# SCR_TC3xx register map
Vendor: Infineon; File version: 1.0
Registers are 8-bit, read-write, reset 0x0 unless marked. A register's access mark holds for its fields unless they carry their own. Offsets are from the block's base; [hi:lo] are bit positions; {n}, {i} and the like mark numbered series.

## SCR_WCAN — SCR Wake-up CAN filter
Base 0x00040000
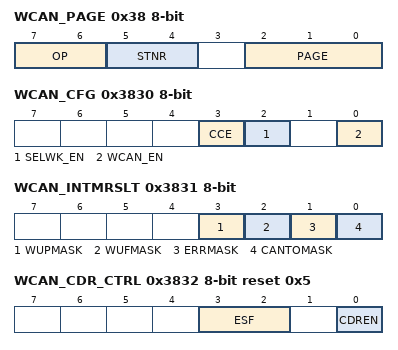
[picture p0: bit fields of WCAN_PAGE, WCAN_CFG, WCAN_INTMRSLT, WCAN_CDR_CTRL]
0x38 WCAN_PAGE — Page Register for WCAN (SFR 0xB8, RMAP 0)
  [7:6] OP — Operation. [w]
    0=PAGE_MANUAL0 (Manual page mode. The value of STNR is ignored and PAGE is directly written.); 1=PAGE_MANUAL1 (Manual page mode. The value of STNR is ignored and PAGE is directly written); 2=PAGE_SAVE (New page programming with automatic page saving. The value written to the bit positions of PAGE is stored. In parallel, the former contents of PAGE are saved in the storage bit field STx indicated by STNR.); 3=PAGE_RESTORE (Automatic restore page action. The value written to the bit positions PAGE is ignored and instead, PAGE is overwritten by the contents of the storage bit field STx indicated by STNR.)
  [5:4] STNR — Storage Number. This number indicates which storage bitfield is the target of the operation defined by bit OP. If OP = 10B, the contents of PAGE are saved in STx before being overwritten with the new value. If OP = 11B, the contents of PAGE are overwritten by the contents of STx. The value written to bitfield PAGE is ignored. [w]
    {v}=MOD_ST{v} (ST{v} is selected) (v=0..3)
  [2:0] PAGE — Page Bits. When written, the value indicates the new page address. When read, the value indicates the currently active page = addr[y:x+1]. [rw]
    {v}=Selection is PAGE{v} (v=0..7)
0x3830 WCAN_CFG — Wake-Up CAN Configuration Register (SFR 0xB0, WCAN_PAGE page 0, RMAP 0)
  [3] CCE — Configuration Change Enable. This bit field enables the configuration of the Bit Timing Registers. It also acts as soft-reset to the Selective Wake-up filter block. It has to be set back to '0' once the bit timing registers are modified for desired baudrate. [rw]
    0=THE_BIT_TIMING_REGISTERS_BTLN (The Bit Timing Registers (BTLn_CTRL), CDR Configuration registers (CDR_CTRL, CDR_UPPER_CTRL, CDR_LOWER_CTRL) and CAN_FD_CTRL may only be read. All attempts to modify them will be ignored.); 1=THE_BIT_TIMING_REGISTERS_AND_CDR (The Bit Timing Registers and CDR Configuration registers may be read and written)
  [2] SELWK_EN — Selective Wake-Up Enable. The Selective Wake-up Enable function enables the protocol handler. The status of the protocol handler is also acknowledged through INTESTAT0.SWACK. The status of the Selective Wakeup Active is given in INTESTAT1.SWKSET. It also serves several functions when enabled. 1.Allows Wake-up source WUF to generate WUF_INT (see Figure "Wake- up Frame Detection"). 2.Allows error counter to generate ERROR_INT (see Figure "Error Counter"), indicated by INTESTAT0.ECOFL. 3.Triggers ERROR_INT and wake-up if there are any changes to the message object registers, indicated by INTESTAT0.MORC. 4.If a SYSERR occurs while SELWK_EN is enabled, then the Selective Wake-up function shall be disabled (ie., this bit field will be reset to 0). It is also indicated by INTESTAT0.ERSEL. [rwh]
    0=SELECTIVE_WAKE_DISABLED; 1=SELECTIVE_WAKE_ENABLED
  [0] WCAN_EN — WCAN Enable. This bit enables or disables the clock to WCAN Selective Wake-Up filter block. [rw]
    0=DISABLE_CLOCK_TO_WCAN_SELECTIVE (Disable Clock to WCAN Selective Wake-Up filter block); 1=ENABLE_CLOCK_TO_WCAN_SELECTIVE (Enable Clock to WCAN Selective Wake-Up filter block)
0x3831 WCAN_INTMRSLT — Wake-Up CAN Interrupt Mask Register (SFR 0xB1, WCAN_PAGE page 0, RMAP 0)
  [3] WUPMASK — Wake-Up Pattern Detected Interrupt Masking. This bit controls the interrupt masking for WUP_INT interrupt. [rw]
    0=WUP_INT_IS_MASKED_NO_INTERRUPT_IS (WUP_INT is masked - no interrupt is triggered); 1=WUP_INT_IS_SIGNALED_AS_AN (WUP_INT is signaled as an interrupt)
  [2] WUFMASK — Wake-Up Frame Interrupt Masking. This bit controls the interrupt masking for WUF_INT interrupt. [rw]
    0=WUF_INT_IS_MASKED_NO_INTERRUPT_IS (WUF_INT is masked - no interrupt is triggered); 1=WUF_INT_IS_SIGNALED_AS_AN (WUF_INT is signaled as an interrupt)
  [1] ERRMASK — SYSERR Masking. This bit controls the interrupt masking for SYSERR interrupt. [rw]
    0=SYSERR_IS_MASKED_NO_INTERRUPT_IS (SYSERR is masked - no interrupt is triggered); 1=SYSERR_IS_SIGNALED_AS_AN (SYSERR is signaled as an interrupt)
  [0] CANTOMASK — CAN Time-Out Masking. This bit controls the interrupt masking for CANTO_INT interrupt. [rw]
    0=CAN_TIME_OUT_IS_MASKED_NO (CAN Time-Out is masked - no interrupt is triggered); 1=CAN_TIME_OUT_IS_SIGNALED_AS_AN (CAN Time-Out is signaled as an interrupt)
0x3832 WCAN_CDR_CTRL reset 0x5 — CDR Control Register (SFR 0xB2, WCAN_PAGE page 0, RMAP 0)
  [3:2] ESF — Error scaling factor. This bitfield defines the number of acquisition cycles on which average on error is calculated. [rw]
    0=ERR_SCALE_FACT8 (8); 1=ERR_SCALE_FACT16 (16 (recommended)); 2=ERR_SCALE_FACT32 (32); 3=ADAPT_AVRGE (Adaptive averaging)
  [0] CDREN — Enable CDR. [rw]
    0=DISABLE_CDR_INTERNAL_BIT_TIME (Disable CDR internal bit time measurement); 1=ENABLE_CDR_INTERNAL_BIT_TIME (Enable CDR internal bit time measurement)
0x3833 WCAN_CDR_UPPER_CTRL reset 0x69 — CDR Upper Limit Control Register (SFR 0xB3, WCAN_PAGE page 0, RMAP 0)
  [7:0] UPPER — CDR Upper Limit. This bitfield defines the upper limit for CDR internal bit time measurement. It should be configured as +5% of BTL1_CTRL value (integer part). [rw]
0x3834 WCAN_CDR_LOWER_CTRL reset 0x5F — CDR Lower Limit Control Register (SFR 0xB4, WCAN_PAGE page 0, RMAP 0)
  [7:0] LOWER — CDR Lower Limit. This bitfield defines the lower limit for CDR internal bit time measurement. It should be configured as -5% of BTL1_CTRL value (integer part). [rw]
0x3835 WCAN_CDR_MEAS_HIGH ro reset 0x64 — CDR Measured High Register (SFR 0xB5, WCAN_PAGE page 0, RMAP 0)
  [7:0] HIGH — CDR Internally Measured High Value. This bitfield shows the internally measured duration of a CAN bus bit as number of fCAN clock cycles (integer part). [rh]
0x3836 WCAN_CDR_MEAS_LOW ro — CDR Measured Low Register (SFR 0xB6, WCAN_PAGE page 0, RMAP 0)
  [5:0] LOW — CDR Internally Measured Low Value. This bitfield shows the internally measured duration of a CAN bus bit as number of fCAN clock cycles (fractional part). [rh]
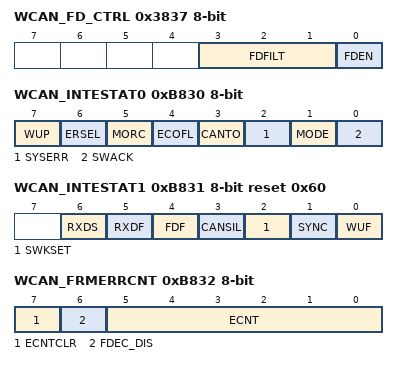
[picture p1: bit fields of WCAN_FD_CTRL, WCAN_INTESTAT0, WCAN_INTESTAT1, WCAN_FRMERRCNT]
0x3837 WCAN_FD_CTRL — CAN FD Control Register (SFR 0xB7, WCAN_PAGE page 0, RMAP 0)
  [3:1] FDFILT — CAN FD Filter Time. This bitfield configures the filter time to detect the dominant bit field in FD phase. Refer to Table "CAN FD dominant bit filter time" for the FD filter time configuration for various baudrates. others, Reserved [rw]
    0=V13_130_NS (13 (130 ns)); 1=V25_250_NS (25 (250 ns)); 2=V48_480_NS (48 (480 ns)); 3=V90_900_NS (90 (900 ns))
  [0] FDEN — CAN FD Tolerant Enable. This bitfield enables or disables the CAN FD tolerant feature. [rw]
    0=DISABLED; 1=ENABLED
0xB830 WCAN_INTESTAT0 ro — Wake-Up CAN Interrupt and Event Status Register 0 (SFR 0xB0, WCAN_PAGE page 1, RMAP 0)
  [7] WUP — Wake-Up Pattern Detected. This bit field is set when a falling edge on RXD (or WUP) is detected, when WCAN is in Standby mode. A software write to INTESTATCLR0.WUPCLR is required to clear this bit field. [rh]
    0=WUP_NOT_DETECTED; 1=WUP_DETECTED_IT_ALSO_TRIGGERS_WUP (WUP detected. It also triggers WUP_INT interrupt when enabled through INTMRSLT.WUPMASK)
  [6] ERSEL — Error Select. A set condition of this flag by hardware has higher priority than a clear through ERSELCLR. [rh]
    0=SYSERR_IS_NOT_SET_WHILE_SELWK_EN (SYSERR is not set while SELWK_EN is enabled); 1=SYSERR_IS_SET_WHILE_SELWK_EN_IS (SYSERR is set while SELWK_EN is enabled)
  [5] MORC — Message Object Register Changed. A set condition of this flag by hardware has higher priority than a clear through MORCCLR. [rh]
    0=MESSAGE_OBJECT_REGISTERS_NOT (Message object registers not modified after SELWK_EN is set); 1=MESSAGE_OBJECT_REGISTERS_WAS (Message object registers was modified after SELWK_EN is set)
  [4] ECOFL — Error Counter Overflow. This bit field shows occurrence of Error Counter overflow. A set condition of this flag by hardware has higher priority than a clear through ECOFLCLR. [rh]
    0=ERROR_COUNTER_HAS_NOT_OVERFLOWED (Error Counter has not overflowed (<= 31)); 1=ERROR_COUNTER_OVERFLOWED_GT_31 (Error Counter overflowed (> 31))
  [3] CANTO — CAN Time-Out Detection. This bit indicates that there was an inactive CAN bus on RXDCO pin within tSILENCE of 750 ms. See section "CAN Message Timeout". A software write to INTESTATCLR0.CANTOCLR is required to reset this bit. [rh]
    0=NORMAL_OPERATION; 1=CAN_TIME_OUT_DETECTED_IT_ALSO (CAN Time-Out detected. It also leads to CANTO_INT interrupt if enabled through CANTOMASK.)
  [2] SYSERR — CAN Wake-Up System Error. The SYSERR indicates a configuration error (MORC), and an error counter overflow condition (ECOFL). [rh]
    0=SELECTIVE_WAKE_MODE_IS_POSSIBLE; 1=SYSTEM_ERROR_DETECTED_WCAN (System Error detected, WCAN enabling not possible. It also leads to SYSERR_INT interrupt trigger if enabled through ERRMASK.)
  [1] MODE — WCAN Mode of Operation. This bitfield indicates the WCAN mode of operation. [rh]
    0=NORMAL_MODE; 1=STANDBY_MODE
  [0] SWACK — Selective Wake-Up Enable Acknowledge. This bit field indicates the acknowledgement of protocol handler enabled/disabled. [rh]
    0=PROTOCOL_HANDLER_IS_DISABLED_AND (Protocol Handler is disabled and configuration of WUF is possible); 1=PROTOCOL_HANDLER_IS_ENABLED_AND (Protocol Handler is enabled and configuration of WUF should not be done)
0xB831 WCAN_INTESTAT1 ro reset 0x60 — Wake-Up CAN Interrupt and Event Status Register 1 (SFR 0xB1, WCAN_PAGE page 1, RMAP 0)
  [6] RXDS — Sampled Receive Data Input. This bit shows the logic state of the sampled received data input signal by the protocol handler. [rh]
    0=DOMINANT; 1=RECESSIVE
  [5] RXDF — Filtered Receive Data Input. This bit shows the logic state of the filtered received data input signal (RXD_filt). [rh]
    0=DOMINANT; 1=RECESSIVE
  [4] FDF — FD Frame Reception. This bit indicates reception of CAN FD frame. After reception of the CAN FD frame is completed, this bit is cleared to ‘0'. [rh]
    0=NO_ACTION; 1=FD_FRAME_IS_BEING_RECEIVED
  [3] CANSIL — CAN Bus Silent Time during Selective Wake Operation. This bit is set if there is no activity on RXDC0 pin on the CAN bus after tSILENCE of 750 ms expired. If any activity is detected on the bus, this bit is reset automatically. tSILENCE is fixed at 750 ms. This bit can also be cleared through bit WCAN_INTESCLR.CANSILCLR. A set condition of this bit has higher priority than a clear through CANSILCLR. 0BtSILENCE not exceeded 1BtSILENCE is exceeded [rh]
  [2] SWKSET — Selective Wake Activity. [rh]
    0=SELECTIVE_WAKE_IS_NOT_ACTIVE; 1=SELECTIVE_WAKE_IS_ACTIVATED
  [1] SYNC — Synchronisation (at least one CAN frame without fail must have been. received) This bit is set when a valid Classical CAN frame is detected and is updatedafter every received Classical CAN frame. This flag is not updated when aCAN FD frame is received. Clearing this flag through SYNCCLR has higherpriority than a set condition by hardware. [rh]
    0=WCAN_FUNCTION_NOT_WORKING_OR_NOT (WCAN function not working or not synchronous to CAN bus); 1=VALID_CAN_FRAME_RECEIVED_WCAN (Valid CAN frame received, WCAN function is synchronous to CAN bus)
  [0] WUF — Wake-Up Frame Detection (acc. ISO 11898-6). This bit shows the status whether a Wake-up Frame has been detected. [rh]
    0=NO_WAKE_UP_FRAME_DETECTED; 1=WAKE_UP_FRAME_DETECTED_IT_ALSO (Wake-Up Frame detected. It also leads to WUF_INT interrupt trigger if enabled through WUFMASK.)
0xB832 WCAN_FRMERRCNT — Wake-Up CAN Error Counter Register (SFR 0xB2, WCAN_PAGE page 1, RMAP 0)
  [7] ECNTCLR — Error Counter Clear Bit. Writing a 1 to this bit clears the error counter FRMERRCNT.ECNT. [w]
  [6] FDEC_DIS — Error Count Disable on CAN FD Frame. This bit is used to describe the behaviour of the Error Counter for FD frames. The value of this bit has no effect if WCAN_FD_CTRL.FDEN = 0. Note:When an FD frame is detected, the error is checked only until the FDF bit of the FD frame. [rw]
    0=ERROR_COUNTER_IS_INCREMENTED_OR (Error counter is incremented or decremented based on correctness of the bitfields in arbitration phase of the FD frame); 1=ERROR_COUNTER_IS_ACTIVE_ONLY_FOR (Error counter is active only for Classical CAN frames, and it is frozen for CAN FD frames)
  [5:0] ECNT ro — SWK CAN Frame Error Counter. If WCAN_FD_CTRL.FDEN = 0, the CAN Frame Error Counter is incremented when an error message or CAN FD frame is received, and decremented on a reception of a correct classical CAN frame, if ECNT>0. If FDEN = 1, the behaviour of the error counter is based on FDEC_DIS bit configuration. See section "Error Counter". [rh]
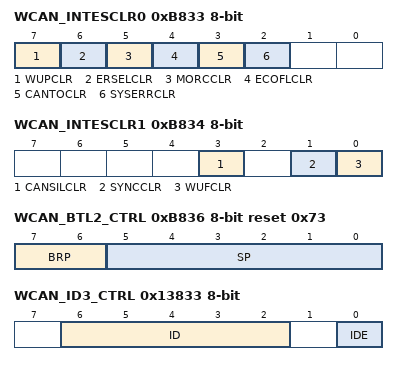
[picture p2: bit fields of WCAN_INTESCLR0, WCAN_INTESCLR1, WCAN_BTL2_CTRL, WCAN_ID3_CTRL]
0xB833 WCAN_INTESCLR0 wo — Wake-Up CAN Interrupt and Event Status Clear Register 0 (SFR 0xB3, WCAN_PAGE page 1, RMAP 0)
  [7] WUPCLR — WUP Clear Bit. Writing a 1 to this bit clears the corresponding status bit INTESTAT0.WUP. [w]
  [6] ERSELCLR — Error Select Clear Bit. Writing a 1 to this bit clears the corresponding status bit INTESTAT0.ERSEL. [w]
  [5] MORCCLR — Message Object Register Changed Clear Bit. Writing a 1 to this bit clears the corresponding status bit INTESTAT0.MORC. [w]
  [4] ECOFLCLR — Error Counter Overflow Clear Bit. Writing a 1 to this bit clears the corresponding status bit INTESTAT0.ECOFL. [w]
  [3] CANTOCLR — CAN Time-Out Detection Clear Bit. Writing a 1 to this bit clears the corresponding status bit INTESTAT0.CANTO. [w]
  [2] SYSERRCLR — CAN WUP System Error Clear Bit. Writing a 1 to this bit clears the corresponding status bit INTESTAT0.SYSERR. [w]
0xB834 WCAN_INTESCLR1 wo — Wake-Up CAN Interrupt and Event Status Clear Register 1 (SFR 0xB4, WCAN_PAGE page 1, RMAP 0)
  [3] CANSILCLR — CAN Silent Time during SWK Operation Clear Bit. Writing a 1 to this bit clears the corresponding status bit INTESTAT1.CANSIL. [w]
  [1] SYNCCLR — Synchronisation (at least one can frame without fail must have been. received) Clear Bit Writing a 1 to this bit clears the corresponding status bit INTESTAT1.SYNC. [w]
  [0] WUFCLR — Wake-up Frame Detection Flag Clear Bit. Writing a 1 to this bit clears the corresponding status bit INTESTAT1.WUF. [w]
0xB835 WCAN_BTL1_CTRL reset 0x64 — Bit Timing Logic 1 Control Register (SFR 0xB5, WCAN_PAGE page 1, RMAP 0)
  [7:0] TBIT — Number of Time Quanta in a Bit Time. This bitfield represents the number of time quanta in a bit time. The time quanta is based on fCAN frequency. [rw]
0xB836 WCAN_BTL2_CTRL reset 0x73 — Bit Timing Logic 2 Control Register (SFR 0xB6, WCAN_PAGE page 1, RMAP 0)
  [7:6] BRP — Baudrate Prescaler. This bitfield defines the scaling factor to derive one time-quanta. [rw]
    0=DIV1 (Division by 1 (100 MHz)); 1=DIV2 (Division by 2 (50 MHz)); 2=DIV4 (Division by 4 (25 MHz)); 3=DIV8 (Division by 8 (12.5 MHz))
  [5:0] SP — Sample Point Position. Represents the sample point position. The sample point position is calculated as given in section "Filter and Sample Point Calculation". 33H represents the sample point position of 79.68 % (~80 %). The value shall be within 2CH to 38H (ie., 67.5 % to 87.5 %). [rw]
0xB837 WCAN_DLC_CTRL — Message Data Length Code Control Register (SFR 0xB7, WCAN_PAGE page 1, RMAP 0)
  [3:0] DLC — Data Length Code. Valid values for the data length are 0 to 8. DLC > 8 will be considered as 8 data bytes, but the truncation will not be visible in this bitfield upon read. [rw]
{0x13830+i} WCAN_ID{i}_CTRL (i=0..2) — Message Identifier Control Register {i} (SFR {0xB0+i}, WCAN_PAGE page 2, RMAP 0)
  [7:0] ID — CAN Identifier. Identifier of a standard message (ID[28:18]) or an extended message (ID[28:0]). For standard identifiers, bits ID[17:0] are "don't care". This bitfield specifies ID{8i+7} to ID{8i}. [rw]
0x13833 WCAN_ID3_CTRL — Message Identifier Control Register 3 (SFR 0xB3, WCAN_PAGE page 2, RMAP 0)
  [6:2] ID — CAN Identifier. Identifier of a standard message (ID[28:18]) or an extended message (ID[28:0]). For standard identifiers, bits ID[17:0] are "don't care". This bitfield specifies ID28 to ID24. [rw]
  [0] IDE — Identified Extension Bit. [rw]
    0=STANDARD_FRAME_WITH_11_BITS (Standard frame with 11 bits identified); 1=EXTENDED_FRAME_WITH_29_BITS (Extended frame with 29 bits identified)
{0x13834+i} WCAN_MASK_ID{i}_CTRL (i=0..2) — Message Identifier Mask Register {i} (SFR {0xB4+i}, WCAN_PAGE page 2, RMAP 0)
  [7:0] MID — Mask for Message Identifier. Mask to filter incoming messages with standard identifiers (MID[28:18]) or extended identifiers (MID[28:0]). For standard identifiers, bits MID[17:0] are "don't care". If a specific bit in MID is set, the corresponding bit in the ID is considered for the ID matching evaluation, otherwise it is considered as "don't care". This bitfield specifies MID{8i+7} to MID{8i}. [rw]
0x13837 WCAN_MASK_ID3_CTRL — Message Identifier Mask Register 3 (SFR 0xB7, WCAN_PAGE page 2, RMAP 0)
  [6:2] MID — Mask for Message Identifier. Mask to filter incoming messages with standard identifiers (MID[28:18]) or extended identifiers (MID[28:0]). For standard identifiers, bits MID[17:0] are "don't care". If a specific bit in MID is set, the corresponding bit in the ID is considered for the ID matching evaluation, otherwise it is considered as "don't care". This bitfield specifies MID28 to MID24. [rw]
{0x1B830+i} WCAN_DATA{i}_CTRL (i=0..7) — DATA Control Register {i} (SFR {0xB0+i}, WCAN_PAGE page 3, RMAP 0)
  [7:0] DATA — CAN Data Byte. These bitfields specify the data bits 7 to 0 that will be compared with corresponding bits of (n+1) data byte of the received CAN frame. [rw]
